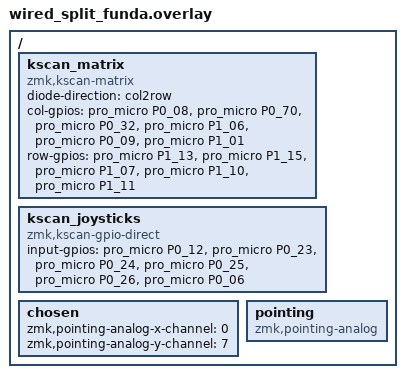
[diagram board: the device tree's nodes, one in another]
/*
 * Overlay para la Funda Teclado 6x5 con 2 Joysticks
 * Definiciones de Hardware
 */

#include <dt-bindings/zmk/matrix_transform.h> // Necesario para kscan_matrix

/ {
    // --- Definición de Pines de Matriz (6x5 = 30 teclas) ---
    kscan_matrix: kscan_matrix {
        compatible = "zmk,kscan-matrix";
        diode-direction = "col2row"; //
        col-gpios
            = <&pro_micro P0_08 (GPIO_ACTIVE_HIGH)>  // Col 0 (D1)
            , <&pro_micro P0_70 (GPIO_ACTIVE_HIGH)>  // Col 1 (D2)
            , <&pro_micro P0_32 (GPIO_ACTIVE_HIGH)>  // Col 2 (D3)
            , <&pro_micro P1_06 (GPIO_ACTIVE_HIGH)>  // Col 3 (D5)
            , <&pro_micro P0_09 (GPIO_ACTIVE_HIGH)>  // Col 4 (D9)
            , <&pro_micro P1_01 (GPIO_ACTIVE_HIGH)>  // Col 5 (D10)
            ; //
        row-gpios
            = <&pro_micro P1_13 (GPIO_ACTIVE_HIGH | GPIO_PULL_DOWN)> // Fila 0 (D18)
            , <&pro_micro P1_15 (GPIO_ACTIVE_HIGH | GPIO_PULL_DOWN)> // Fila 1 (D19)
            , <&pro_micro P1_07 (GPIO_ACTIVE_HIGH | GPIO_PULL_DOWN)> // Fila 2
            , <&pro_micro P1_10 (GPIO_ACTIVE_HIGH | GPIO_PULL_DOWN)> // Fila 3
            , <&pro_micro P1_11 (GPIO_ACTIVE_HIGH | GPIO_PULL_DOWN)> // Fila 4
            ; //
    };

    // --- Definición de Pines de Joysticks (Digitales) ---
    kscan_joysticks: kscan_joysticks {
        compatible = "zmk,kscan-gpio-direct"; //
        input-gpios
            // Joystick 1 (Digital - Modificadores)
            = <&pro_micro P0_12 (GPIO_ACTIVE_HIGH | GPIO_PULL_DOWN)>  // Joy1 Arriba (D22)
            , <&pro_micro P0_23 (GPIO_ACTIVE_HIGH | GPIO_PULL_DOWN)>  // Joy1 Abajo (D23)
            , <&pro_micro P0_24 (GPIO_ACTIVE_HIGH | GPIO_PULL_DOWN)>  // Joy1 Izquierda (D24)
            , <&pro_micro P0_25 (GPIO_ACTIVE_HIGH | GPIO_PULL_DOWN)>  // Joy1 Derecha (D25)
            , <&pro_micro P0_26 (GPIO_ACTIVE_HIGH | GPIO_PULL_DOWN)>  // Joy1 Botón (D26)
            
            // Joystick 2 (Botón del Mouse)
            , <&pro_micro P0_06 (GPIO_ACTIVE_HIGH | GPIO_PULL_DOWN)>  // Joy2 Botón (D0)
            ; //
    };

    // --- Definición de Ejes de Joystick 2 (Analógico - Mouse) ---
    chosen {
        zmk,pointing-analog-x-channel = <0>; // P0.02 (D20) es ADC Canal 0
        zmk,pointing-analog-y-channel = <7>; // P0.31 (D21) es ADC Canal 7
    }; //

    pointing: pointing {
        compatible = "zmk,pointing-analog";
    }; //
};
